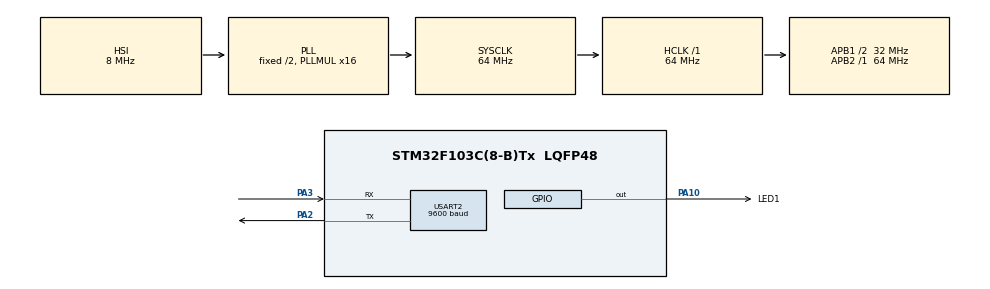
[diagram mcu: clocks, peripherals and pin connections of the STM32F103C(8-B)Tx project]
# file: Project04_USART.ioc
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Mcu.Family=STM32F1
Mcu.Name=STM32F103C(8-B)Tx
Mcu.Package=LQFP48
NVIC.PriorityGroup=NVIC_PRIORITYGROUP_2
NVIC.USART2_IRQn=true\:0\:0\:true\:false\:true\:true\:true
PA10.GPIO_Label=LED1
PA10.Signal=GPIO_Output
PA13.Mode=Serial_Wire
PA13.Signal=SYS_JTMS-SWDIO
PA14.Mode=Serial_Wire
PA14.Signal=SYS_JTCK-SWCLK
PA2.Mode=Asynchronous
PA2.Signal=USART2_TX
PA3.Mode=Asynchronous
PA3.Signal=USART2_RX
ProjectManager.HeapSize=0x200
ProjectManager.StackSize=0x400
ProjectManager.TargetToolchain=MDK-ARM V5
RCC.AHBFreq_Value=64000000
RCC.APB1CLKDivider=RCC_HCLK_DIV2
RCC.APB1Freq_Value=32000000
RCC.APB1TimFreq_Value=64000000
RCC.APB2Freq_Value=64000000
RCC.APB2TimFreq_Value=64000000
RCC.HCLKFreq_Value=64000000
RCC.PLLMUL=RCC_PLL_MUL16
RCC.SYSCLKFreq_VALUE=64000000
RCC.SYSCLKSource=RCC_SYSCLKSOURCE_PLLCLK
RCC.USBFreq_Value=64000000
USART2.BaudRate=9600
USART2.VirtualMode=VM_ASYNC
board=custom

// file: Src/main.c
/* USER CODE BEGIN Header */
/**
  ******************************************************************************
  * @file           : main.c
  * @brief          : Main program body
  ******************************************************************************
  * @attention
  *
  * <h2><center>&copy; Copyright (c) 2021 STMicroelectronics.
  * All rights reserved.</center></h2>
  *
  * This software component is licensed by ST under BSD 3-Clause license,
  * the "License"; You may not use this file except in compliance with the
  * License. You may obtain a copy of the License at:
  *                        opensource.org/licenses/BSD-3-Clause
  *
  ******************************************************************************
  */
/* USER CODE END Header */

#include "main.h"
#include "usart.h"
#include "gpio.h"

/* USER CODE BEGIN PV */

// 外部变量
extern uint8_t huart2_data; // 串口2数据

/* USER CODE END PV */

void SystemClock_Config(void);

int main(void)
{
  /* USER CODE BEGIN 1 */
    uint8_t str_buf[] = "[Log] USART2 is working.\r\n";

  /* USER CODE END 1 */

  /* MCU Configuration--------------------------------------------------------*/

  /* Reset of all peripherals, Initializes the Flash interface and the Systick. */
  HAL_Init();

  /* Configure the system clock */
  SystemClock_Config();

  /* Initialize all configured peripherals */
  MX_GPIO_Init();
  MX_USART2_UART_Init();
  /* USER CODE BEGIN 2 */

    HAL_UART_Receive_IT(&huart2, &huart2_data, 1); // 接收一个串口2的数据

  /* USER CODE END 2 */

  /* Infinite loop */
  while (1)
  {
        HAL_UART_Transmit(&huart2, str_buf, sizeof(str_buf), 1000);
        HAL_Delay(5000);
  }
}

void SystemClock_Config(void)
{
  RCC_OscInitTypeDef RCC_OscInitStruct = {0};
  RCC_ClkInitTypeDef RCC_ClkInitStruct = {0};

  /** Initializes the CPU, AHB and APB busses clocks
  */
  RCC_OscInitStruct.OscillatorType = RCC_OSCILLATORTYPE_HSI;
  RCC_OscInitStruct.HSIState = RCC_HSI_ON;
  RCC_OscInitStruct.HSICalibrationValue = RCC_HSICALIBRATION_DEFAULT;
  RCC_OscInitStruct.PLL.PLLState = RCC_PLL_ON;
  RCC_OscInitStruct.PLL.PLLSource = RCC_PLLSOURCE_HSI_DIV2;
  RCC_OscInitStruct.PLL.PLLMUL = RCC_PLL_MUL16;
  if (HAL_RCC_OscConfig(&RCC_OscInitStruct) != HAL_OK)
  {
    Error_Handler();
  }
  /** Initializes the CPU, AHB and APB busses clocks
  */
  RCC_ClkInitStruct.ClockType = RCC_CLOCKTYPE_HCLK|RCC_CLOCKTYPE_SYSCLK
                              |RCC_CLOCKTYPE_PCLK1|RCC_CLOCKTYPE_PCLK2;
  RCC_ClkInitStruct.SYSCLKSource = RCC_SYSCLKSOURCE_PLLCLK;
  RCC_ClkInitStruct.AHBCLKDivider = RCC_SYSCLK_DIV1;
  RCC_ClkInitStruct.APB1CLKDivider = RCC_HCLK_DIV2;
  RCC_ClkInitStruct.APB2CLKDivider = RCC_HCLK_DIV1;

  if (HAL_RCC_ClockConfig(&RCC_ClkInitStruct, FLASH_LATENCY_2) != HAL_OK)
  {
    Error_Handler();
  }
}

void Error_Handler(void)
{
}

/************************ (C) COPYRIGHT STMicroelectronics *****END OF FILE****/
